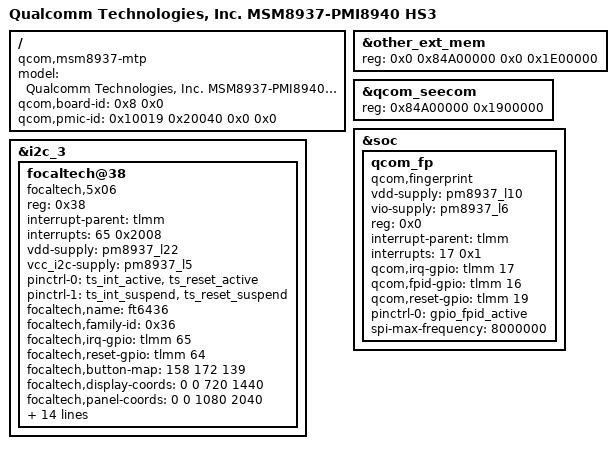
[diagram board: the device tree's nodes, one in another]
/*
 * Copyright (c) 2018, The Linux Foundation. All rights reserved.
 *
 * This program is free software; you can redistribute it and/or modify
 * it under the terms of the GNU General Public License version 2 and
 * only version 2 as published by the Free Software Foundation.
 *
 * This program is distributed in the hope that it will be useful,
 * but WITHOUT ANY WARRANTY; without even the implied warranty of
 * MERCHANTABILITY or FITNESS FOR A PARTICULAR PURPOSE.  See the
 * GNU General Public License for more details.
 */

/dts-v1/;

#include "msm8937.dtsi"
#include "msm-pmi8940.dtsi"
#include "msm8937-mtp.dtsi"
#include "msm8937-pmi8940-mtp.dtsi"
#include "hs3/msm8937-mdss-panels-hs3.dtsi"
#include "hs3/msm8937-pinctrl-hs3.dtsi"

/ {
	model = "Qualcomm Technologies, Inc. MSM8937-PMI8940 HS3";
	compatible = "qcom,msm8937-mtp", "qcom,msm8937", "qcom,mtp";
	qcom,board-id = <0x8 0x0>;
	qcom,pmic-id = <0x10019 0x20040 0x0 0x0>;
};

&other_ext_mem {
	reg = <0x0 0x84A00000 0x0 0x1E00000>;
	
};

&qcom_seecom {
	reg = <0x84A00000 0x1900000>;
};

&soc {
	/delete-node/ hbtp;
		qcom_fp {
		status = "ok";
		compatible = "qcom,fingerprint";
		vdd-supply = <&pm8937_l10>;
		vio-supply = <&pm8937_l6>;
		reg = <0x0>;
		interrupt-parent = <&tlmm>;
		interrupts = <17 0x1>;
		qcom,irq-gpio = <&tlmm 17 0>;
		qcom,fpid-gpio = <&tlmm 16 0>;
		qcom,reset-gpio = <&tlmm 19 0>;
		pinctrl-names = "tlmm_gpio_fpid_active";
		pinctrl-0 = <&gpio_fpid_active>;
		spi-max-frequency = <8000000>;

	};
};

&i2c_3{
	status = "okay";
		focaltech@38 {
			compatible = "focaltech,5x06";
			reg = <0x38>;
			interrupt-parent = <&tlmm>;
			interrupts = <65 0x2008>;
			vdd-supply = <&pm8937_l22>;
			vcc_i2c-supply = <&pm8937_l5>;
			pinctrl-names = "pmx_ts_active","pmx_ts_suspend";
			pinctrl-0 = <&ts_int_active &ts_reset_active>;
			pinctrl-1 = <&ts_int_suspend &ts_reset_suspend>;
			focaltech,name = "ft6436";
			focaltech,family-id = <0x36>;
			focaltech,irq-gpio = <&tlmm 65 0x0>;
			focaltech,reset-gpio = <&tlmm 64 0x0>;
			focaltech,button-map = <158 172 139>;
			focaltech,display-coords = <0 0 720 1440>;
			focaltech,panel-coords = <0 0 1080 2040>;
			focaltech,no-force-update;
			focaltech,i2c-pull-up;
			focaltech,group-id = <1>;
			focaltech,hard-reset-delay-ms = <20>;
			focaltech,soft-reset-delay-ms = <200>;
			focaltech,num-max-touches = <5>;
			focaltech,fw-delay-aa-ms = <30>;
			focaltech,fw-delay-55-ms = <30>;
			focaltech,fw-upgrade-id1 = <0x79>;
			focaltech,fw-upgrade-id2 = <0x18>;
			focaltech,fw-delay-readid-ms = <10>;
			focaltech,fw-delay-era-flsh-ms = <2000>;
			focaltech,fw-auto-cal;
			focaltech,ignore-id-check;
		};
};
